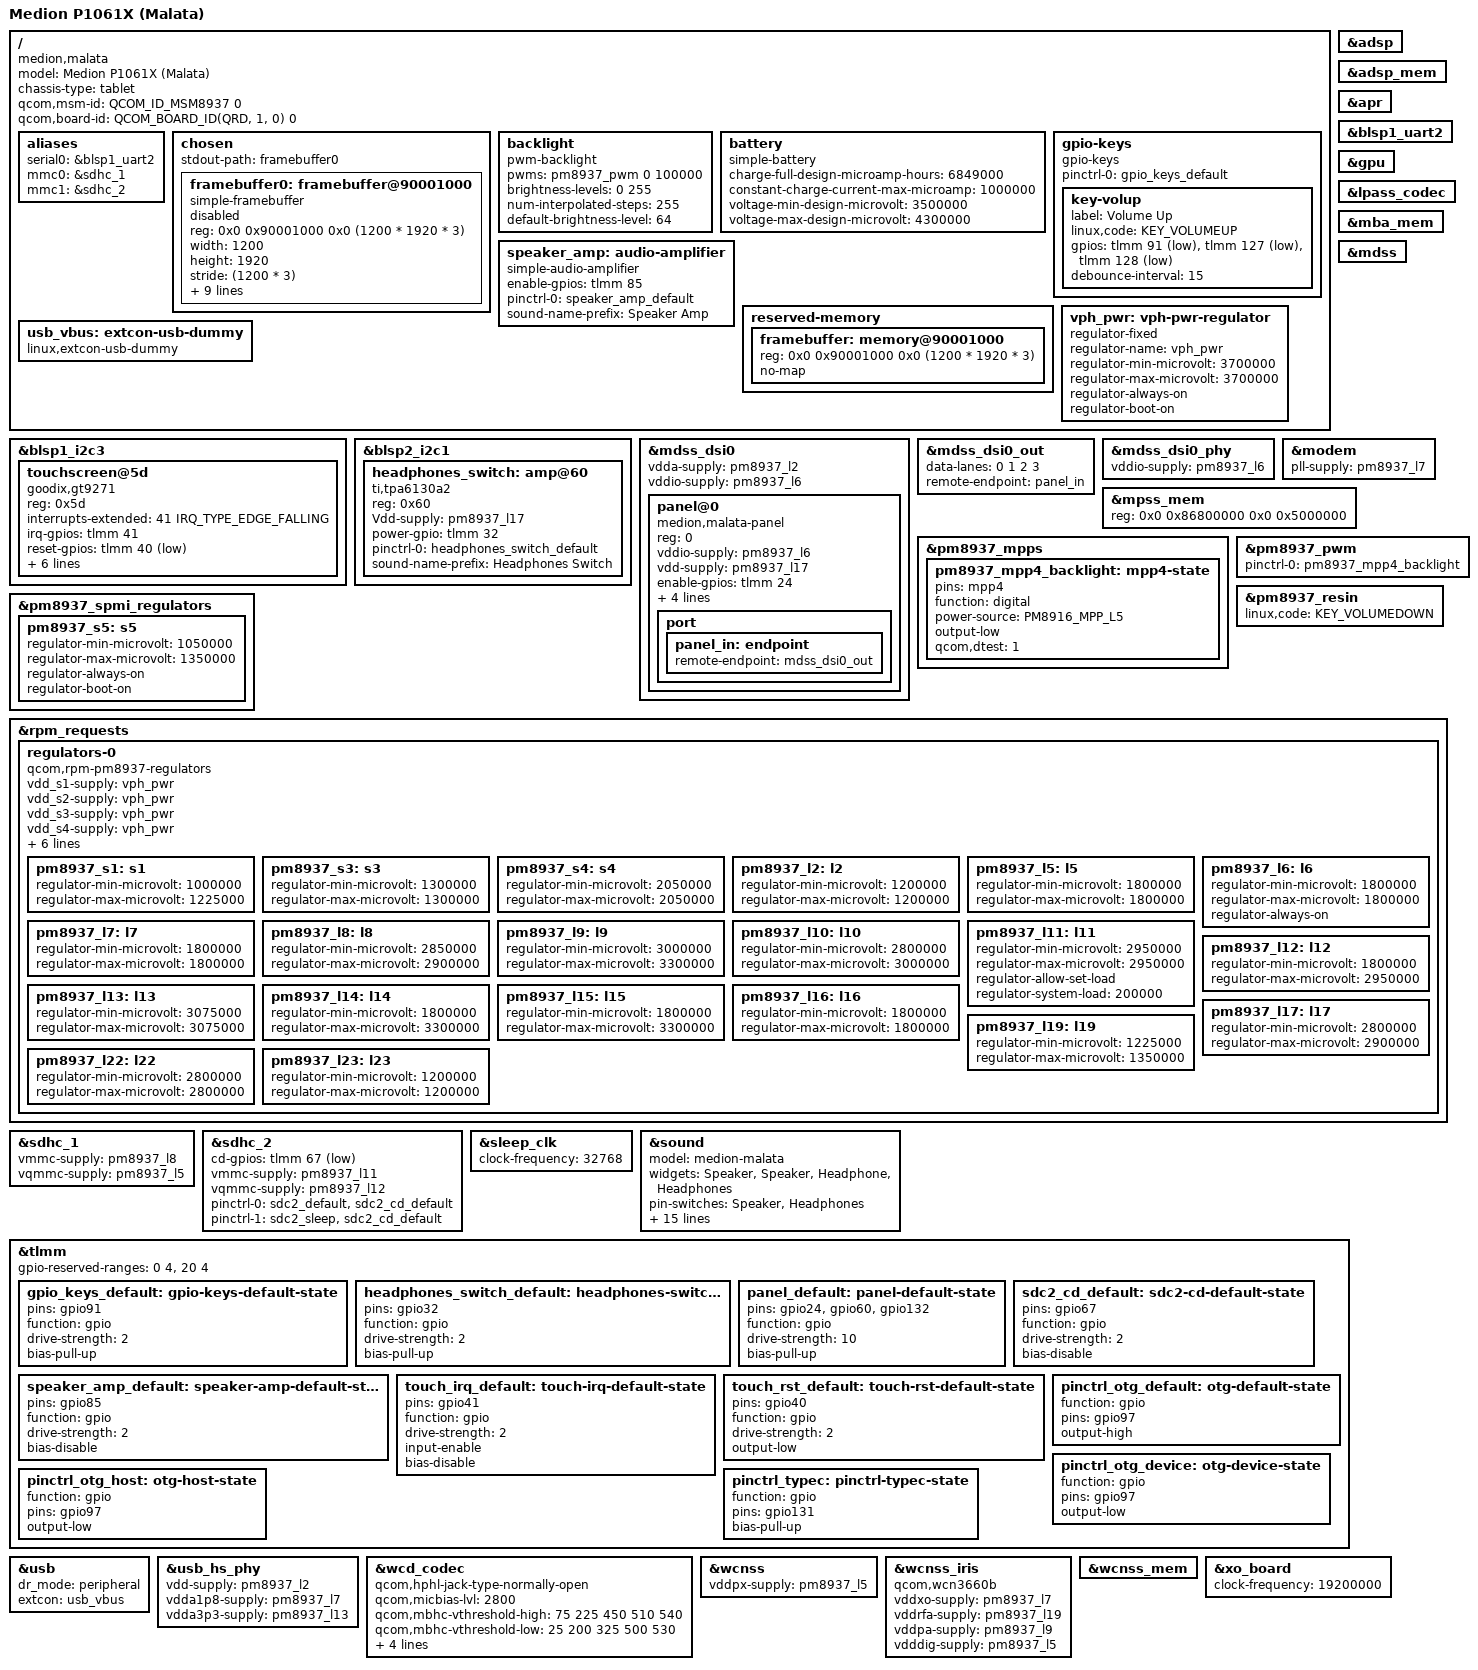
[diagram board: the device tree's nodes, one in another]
// SPDX-License-Identifier: BSD-3-Clause

/dts-v1/;

#include <dt-bindings/arm/qcom,ids.h>
#include <dt-bindings/gpio/gpio.h>
#include <dt-bindings/interrupt-controller/irq.h>
#include <dt-bindings/leds/common.h>
#include <dt-bindings/pinctrl/qcom,pmic-mpp.h>

#include "msm8937.dtsi"
#include "pm8937.dtsi"
#include "pmi8950.dtsi"
#include "msm8937-qdsp6.dtsi"

/ {
	model = "Medion P1061X (Malata)";
	compatible = "medion,malata", "qcom,msm8937";
	chassis-type = "tablet";

	qcom,msm-id = <QCOM_ID_MSM8937 0>;
	qcom,board-id = <QCOM_BOARD_ID(QRD, 1, 0) 0>;
	//qcom,board-id = <QCOM_BOARD_ID_QRD 0x00>;

	aliases {
		serial0 = &blsp1_uart2;
		mmc0 = &sdhc_1;
		mmc1 = &sdhc_2;
	};

	chosen {
		#address-cells = <2>;
		#size-cells = <2>;
		ranges;

		//stdout-path = "serial0:115200n8";
		stdout-path = "framebuffer0";

		framebuffer0: framebuffer@90001000 {
			compatible = "simple-framebuffer";
			reg = <0x0 0x90001000 0x0 (1200 * 1920 * 3)>;
			width = <1200>;
			height = <1920>;
			stride = <(1200 * 3)>;
			format = "r8g8b8";

			clocks = <&gcc GCC_MDSS_AHB_CLK>,
				 <&gcc GCC_MDSS_AXI_CLK>,
				 <&gcc GCC_MDSS_VSYNC_CLK>,
				 <&gcc GCC_MDSS_MDP_CLK>,
				 <&gcc GCC_MDSS_BYTE0_CLK>,
				 <&gcc GCC_MDSS_PCLK0_CLK>,
				 <&gcc GCC_MDSS_ESC0_CLK>;
			power-domains = <&gcc MDSS_GDSC>;
			status = "disabled";
		};
	};

	backlight: backlight {
		compatible = "pwm-backlight";
		pwms = <&pm8937_pwm 0 100000>;

		brightness-levels = <0 255>;
		num-interpolated-steps = <255>;
		default-brightness-level = <64>;
	};

	battery: battery {
		compatible = "simple-battery";

		charge-full-design-microamp-hours = <6849000>;
		constant-charge-current-max-microamp = <1000000>;
		voltage-min-design-microvolt = <3500000>;
		voltage-max-design-microvolt = <4300000>;
	};

	gpio-keys {
		compatible = "gpio-keys";

		pinctrl-0 = <&gpio_keys_default>;
		pinctrl-names = "default";

		key-volup {
			label = "Volume Up";
			linux,code = <KEY_VOLUMEUP>;
			gpios = <&tlmm 91 GPIO_ACTIVE_LOW>,<&tlmm 127 GPIO_ACTIVE_LOW>,<&tlmm 128 GPIO_ACTIVE_LOW> ;
			debounce-interval = <15>;
		};
	};

	speaker_amp: audio-amplifier {
		compatible = "simple-audio-amplifier";
		enable-gpios = <&tlmm 85 GPIO_ACTIVE_HIGH>;

		pinctrl-0 = <&speaker_amp_default>;
		pinctrl-names = "default";

		sound-name-prefix = "Speaker Amp";
	};
	
	reserved-memory {
		framebuffer: memory@90001000 {
			//reg = <0x00 0x90001000 0x00 0x1400000>;
			reg = <0x0 0x90001000 0x0 (1200 * 1920 * 3)>;
			no-map;
		};
	};

	vph_pwr: vph-pwr-regulator {
		compatible = "regulator-fixed";
		regulator-name = "vph_pwr";
		regulator-min-microvolt = <3700000>;
		regulator-max-microvolt = <3700000>;
		regulator-always-on;
		regulator-boot-on;
	};

	usb_vbus: extcon-usb-dummy {
		compatible = "linux,extcon-usb-dummy";
	};
};

&adsp {
	status = "okay";
};

&adsp_mem {
	status = "okay";
};

&apr {
	status = "okay";
};

&blsp1_i2c3 {
	status = "okay";

	touchscreen@5d {
		compatible = "goodix,gt9271";
		reg = <0x5d>;

		interrupts-extended = <41 IRQ_TYPE_EDGE_FALLING>;
		irq-gpios = <&tlmm 41 GPIO_ACTIVE_HIGH>;
		reset-gpios = <&tlmm 40 GPIO_ACTIVE_LOW>;

		AVDD28-supply = <&pm8937_l17>;
		VDDIO-supply = <&pm8937_l6>;

		pinctrl-names = "default";
		pinctrl-0 = <&touch_rst_default &touch_irq_default>;

		touchscreen-inverted-y;
		touchscreen-swapped-x-y;
	};
};

&blsp1_uart2 {
	status = "okay";
};

&blsp2_i2c1 {
	status = "okay";

	headphones_switch: amp@60 {
		compatible = "ti,tpa6130a2";
		reg = <0x60>;

		Vdd-supply = <&pm8937_l17>;
		power-gpio = <&tlmm 32 GPIO_ACTIVE_HIGH>;

		pinctrl-names = "default";//,"sleep";
		pinctrl-0 = <&headphones_switch_default>;
		//pinctrl-1 = <&headphones_switch_sleep>;

		sound-name-prefix = "Headphones Switch";
	};
};

&gpu {
	status = "okay";
};

&lpass_codec {
	status = "okay";
};

&mba_mem {
	status = "okay";
};

&mdss {
	status = "okay";
};

&mdss_dsi0 {
	vdda-supply = <&pm8937_l2>;
	vddio-supply = <&pm8937_l6>;

	status = "okay";

	panel@0 {
		compatible = "medion,malata-panel","malata,gama-wuxga";
		reg = <0>;
		
		vddio-supply = <&pm8937_l6>;
		vdd-supply = <&pm8937_l17>;
		
		enable-gpios = <&tlmm 24 GPIO_ACTIVE_HIGH>;
		blen-gpios = <&tlmm 132 GPIO_ACTIVE_HIGH>;
		
		reset-gpios = <&tlmm 60 GPIO_ACTIVE_LOW>;

		backlight = <&backlight>;

		pinctrl-0 = <&panel_default>;
		pinctrl-names = "default";

		port {
			panel_in: endpoint {
				remote-endpoint = <&mdss_dsi0_out>;
			};
		};
	};
};

&mdss_dsi0_out {
	data-lanes = <0 1 2 3>;
	remote-endpoint = <&panel_in>;
};

&mdss_dsi0_phy {
	vddio-supply = <&pm8937_l6>;

	status = "okay";
};

&modem {
	pll-supply = <&pm8937_l7>;

	status = "okay";
};

&mpss_mem {
	reg = <0x0 0x86800000 0x0 0x5000000>;
	status = "okay";
};

&pm8937_mpps {
	pm8937_mpp4_backlight: mpp4-state {
		pins = "mpp4";
		function = "digital";      /* Entspricht qcom,mode = <0x01> */
		power-source = <PM8916_MPP_L5>;        /* Entspricht qcom,vin-sel (3 = L5) */
		output-low;
		qcom,dtest = <1>;
	};
};

&pm8937_pwm {
	pinctrl-names = "default";
	pinctrl-0 = <&pm8937_mpp4_backlight>;

	status = "okay";
};

&pm8937_resin {
	linux,code = <KEY_VOLUMEDOWN>;

	status = "okay";
};

&pm8937_spmi_regulators {
	pm8937_s5: s5 {
		regulator-min-microvolt = <1050000>;
		regulator-max-microvolt = <1350000>;
		regulator-always-on;
		regulator-boot-on;
	};
};
/*
&pmi8950_fg {
	monitored-battery = <&battery>;
	//power-supplies = <&pmi8950_smbcharger>;
	status = "okay";
};

&pmi8950_smbcharger {
	monitored-battery = <&battery>;
	status = "okay";
};*/

&rpm_requests {
	regulators-0 {
		compatible = "qcom,rpm-pm8937-regulators";

		vdd_s1-supply = <&vph_pwr>;
		vdd_s2-supply = <&vph_pwr>;
		vdd_s3-supply = <&vph_pwr>;
		vdd_s4-supply = <&vph_pwr>;

		vdd_l1_l19-supply = <&pm8937_s3>;
		vdd_l2_l23-supply = <&pm8937_s3>;
		vdd_l3-supply = <&pm8937_s3>;
		vdd_l4_l5_l6_l7_l16-supply = <&pm8937_s4>;
		vdd_l8_l11_l12_l17_l22-supply = <&vph_pwr>;
		vdd_l9_l10_l13_l14_l15_l18-supply = <&vph_pwr>;

		pm8937_s1: s1 {
			regulator-min-microvolt = <1000000>;
			regulator-max-microvolt = <1225000>;
		};

		pm8937_s3: s3 {
			regulator-min-microvolt = <1300000>;
			regulator-max-microvolt = <1300000>;
		};

		pm8937_s4: s4 {
			regulator-min-microvolt = <2050000>;
			regulator-max-microvolt = <2050000>;
		};

		pm8937_l2: l2 {
			regulator-min-microvolt = <1200000>;
			regulator-max-microvolt = <1200000>;
		};

		pm8937_l5: l5 {
			regulator-min-microvolt = <1800000>;
			regulator-max-microvolt = <1800000>;
		};

		pm8937_l6: l6 {
			regulator-min-microvolt = <1800000>;
			regulator-max-microvolt = <1800000>;
			regulator-always-on;
		};

		pm8937_l7: l7 {
			regulator-min-microvolt = <1800000>;
			regulator-max-microvolt = <1800000>;
		};

		pm8937_l8: l8 {
			regulator-min-microvolt = <2850000>;
			regulator-max-microvolt = <2900000>;
		};

		pm8937_l9: l9 {
			regulator-min-microvolt = <3000000>;
			regulator-max-microvolt = <3300000>;
		};

		pm8937_l10: l10 {
			regulator-min-microvolt = <2800000>;
			regulator-max-microvolt = <3000000>;
		};

		pm8937_l11: l11 {
			regulator-min-microvolt = <2950000>;
			regulator-max-microvolt = <2950000>;
			regulator-allow-set-load;
			regulator-system-load = <200000>;
		};

		pm8937_l12: l12 {
			regulator-min-microvolt = <1800000>;
			regulator-max-microvolt = <2950000>;
		};

		pm8937_l13: l13 {
			regulator-min-microvolt = <3075000>;
			regulator-max-microvolt = <3075000>;
		};

		pm8937_l14: l14 {
			regulator-min-microvolt = <1800000>;
			regulator-max-microvolt = <3300000>;
		};

		pm8937_l15: l15 {
			regulator-min-microvolt = <1800000>;
			regulator-max-microvolt = <3300000>;
		};

		pm8937_l16: l16 {
			regulator-min-microvolt = <1800000>;
			regulator-max-microvolt = <1800000>;
		};

		pm8937_l17: l17 {
			regulator-min-microvolt = <2800000>;
			regulator-max-microvolt = <2900000>;
		};

		pm8937_l19: l19 {
			regulator-min-microvolt = <1225000>;
			regulator-max-microvolt = <1350000>;
		};

		pm8937_l22: l22 {
			regulator-min-microvolt = <2800000>;
			regulator-max-microvolt = <2800000>;
		};

		pm8937_l23: l23 {
			regulator-min-microvolt = <1200000>;
			regulator-max-microvolt = <1200000>;
		};
	};
};

&sdhc_1 {
	vmmc-supply = <&pm8937_l8>;
	vqmmc-supply = <&pm8937_l5>;
	status = "okay";
};

&sdhc_2 {
	cd-gpios = <&tlmm 67 GPIO_ACTIVE_LOW>;
	vmmc-supply = <&pm8937_l11>;
	vqmmc-supply = <&pm8937_l12>;
	pinctrl-0 = <&sdc2_default &sdc2_cd_default>;
	pinctrl-1 = <&sdc2_sleep &sdc2_cd_default>;
	pinctrl-names = "default", "sleep";
	status = "okay";
};

&sleep_clk {
	clock-frequency = <32768>;
};

&sound {
	model = "medion-malata";

	widgets =
		"Speaker", "Speaker",
		"Headphone", "Headphones";
	pin-switches = "Speaker", "Headphones";
	audio-routing =
		"Speaker", "Speaker Amp OUTL",
		"Speaker", "Speaker Amp OUTR",
		"Speaker Amp INL", "HPHL",
		"Speaker Amp INR", "HPHR",
		"Headphones", "Headphones Switch OUTL",
		"Headphones", "Headphones Switch OUTR",
		"Headphones Switch INL", "HPHL",
		"Headphones Switch INR", "HPHR",
		"AMIC1", "MIC BIAS External1",
		"AMIC2", "MIC BIAS Internal2",
		"AMIC3", "MIC BIAS External1",
		"MM_DL1", "MultiMedia1 Playback",
		"MM_DL3", "MultiMedia3 Playback",
		"MM_DL4", "MultiMedia4 Playback",
		"MultiMedia2 Capture", "MM_UL2";

	aux-devs = <&speaker_amp>, <&headphones_switch>;
	
	status = "okay";
};

&tlmm {
	gpio-reserved-ranges = <0 4>, <20 4>;

	gpio_keys_default: gpio-keys-default-state {
		pins = "gpio91";
		function = "gpio";
		drive-strength = <2>;
		bias-pull-up;
	};

	headphones_switch_default: headphones-switch-default-state {
		pins = "gpio32";
		function = "gpio";
		drive-strength = <2>;
		bias-pull-up;
	};

	panel_default: panel-default-state {
		pins = "gpio24","gpio60","gpio132";
		function = "gpio";
		drive-strength = <10>;
		bias-pull-up;
	};

	sdc2_cd_default: sdc2-cd-default-state {
		pins = "gpio67";
		function = "gpio";
		drive-strength = <2>;
		bias-disable;
	};

	speaker_amp_default: speaker-amp-default-state {
		pins = "gpio85";
		function = "gpio";
		drive-strength = <2>;
		bias-disable;
		//output-high;
	};

	touch_irq_default: touch-irq-default-state {
		pins = "gpio41";
		function = "gpio";
		drive-strength = <2>;
		input-enable;
		bias-disable;
	};

	touch_rst_default: touch-rst-default-state {
		pins = "gpio40";
		function = "gpio";
		drive-strength = <2>;
		output-low;
	};

	pinctrl_otg_default: otg-default-state {
		function = "gpio";
		pins = "gpio97";
		output-high;
	};

	pinctrl_otg_device: otg-device-state {
		function = "gpio";
		pins = "gpio97";
		output-low;
	};

	pinctrl_otg_host: otg-host-state {
		function = "gpio";
		pins = "gpio97";
		output-low;
	};

	pinctrl_typec: pinctrl-typec-state {
		function = "gpio";
		pins = "gpio131";
		bias-pull-up;
	};
};

&usb {
	dr_mode = "peripheral";
	//extcon = <&pmi8950_smbcharger>, <&usb_vbus>;
	extcon = <&usb_vbus>;
	status = "okay";
};

&usb_hs_phy {
	vdd-supply = <&pm8937_l2>;
	vdda1p8-supply = <&pm8937_l7>;
	vdda3p3-supply = <&pm8937_l13>;
	status = "okay";
};

&wcd_codec {
	qcom,hphl-jack-type-normally-open;
	qcom,micbias-lvl = <2800>;
	qcom,mbhc-vthreshold-high = <75 225 450 510 540>;
	qcom,mbhc-vthreshold-low = <25 200 325 500 530>;
	qcom,micbias1-ext-cap;

	vdd-cdc-io-supply = <&pm8937_l5>;
	vdd-cdc-tx-rx-cx-supply = <&pm8937_s4>;
	vdd-micbias-supply = <&pm8937_l13>;
	status = "okay";
};

&wcnss {
	vddpx-supply = <&pm8937_l5>;
	status = "okay";
};

&wcnss_iris { //fertig
	compatible = "qcom,wcn3660b";
	vddxo-supply = <&pm8937_l7>;
	vddrfa-supply = <&pm8937_l19>;
	vddpa-supply = <&pm8937_l9>;
	vdddig-supply = <&pm8937_l5>;
};

&wcnss_mem {
	status = "okay";
};

&xo_board {
	clock-frequency = <19200000>;
};
